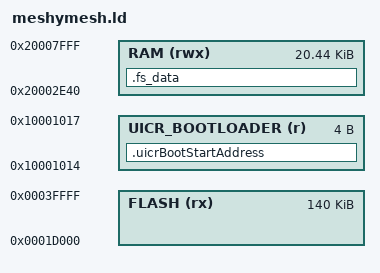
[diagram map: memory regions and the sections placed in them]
/* Linker script to configure memory regions. */

SEARCH_DIR(.)
GROUP(-lgcc -lc -lnosys)

MEMORY
{
  FLASH (rx) : ORIGIN = 0x1d000, LENGTH = 0x23000
  RAM (rwx) :  ORIGIN = 0x20002e40, LENGTH = 0x51c0

  /** Location in UICR where bootloader start address is stored. */
  UICR_BOOTLOADER (r) : ORIGIN = 0x10001014, LENGTH = 0x04
}

SECTIONS
{
  .fs_data :
  {
    PROVIDE(__start_fs_data = .);
    KEEP(*(.fs_data))
    PROVIDE(__stop_fs_data = .);
  } > RAM

  /* Ensures the Bootloader start address in flash is written to UICR when flashing the image. */
  .uicrBootStartAddress :
  {
    KEEP(*(.uicrBootStartAddress))
  } > UICR_BOOTLOADER
} INSERT AFTER .data;

INCLUDE "nrf5x_common.ld"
